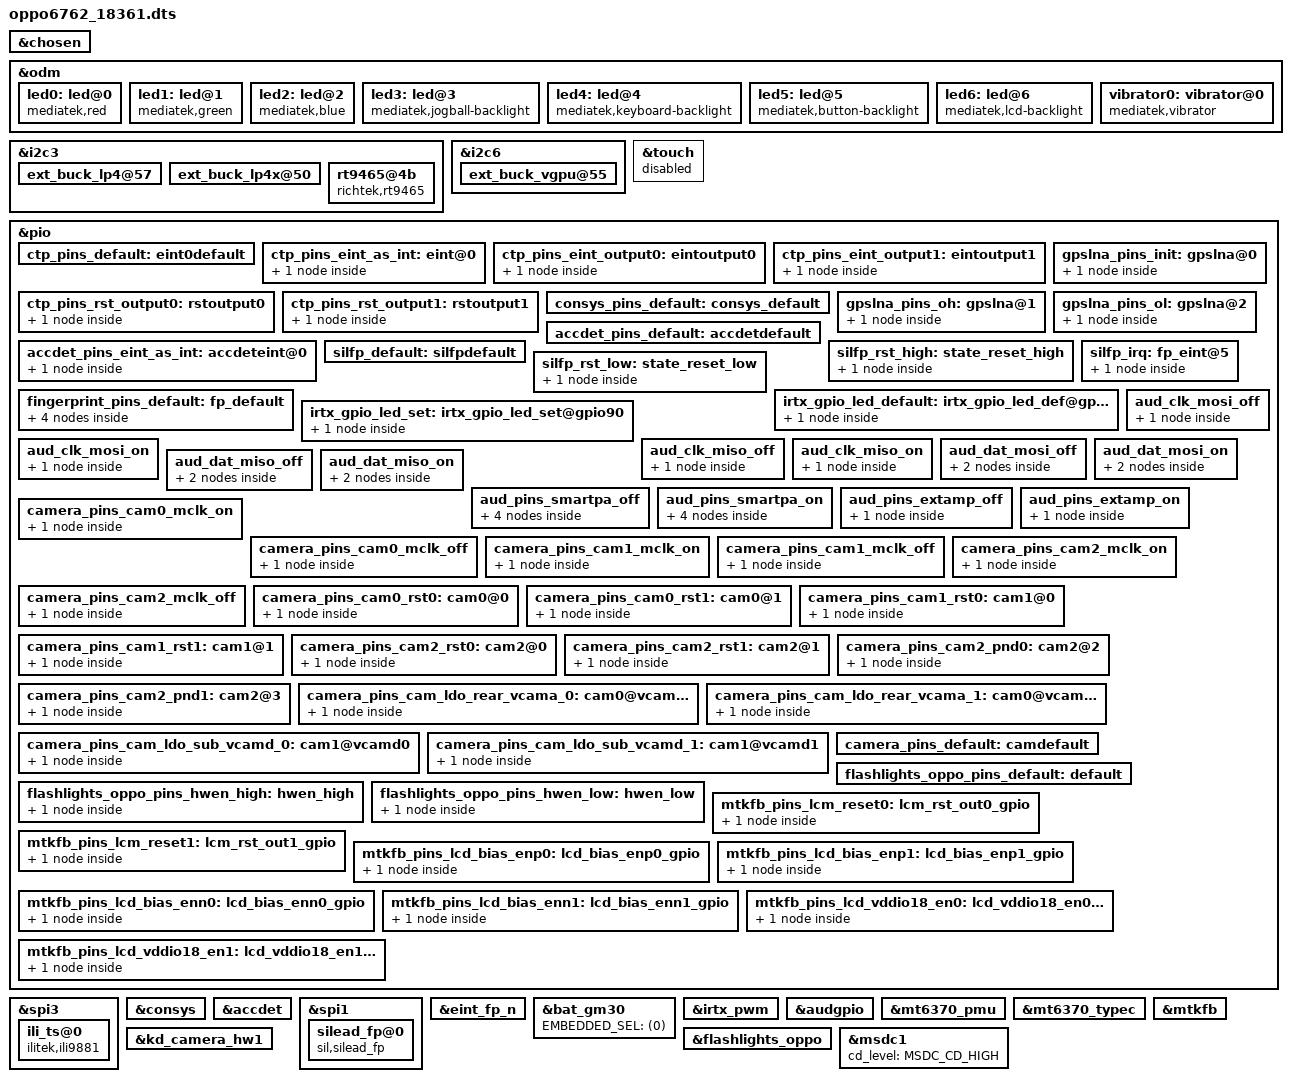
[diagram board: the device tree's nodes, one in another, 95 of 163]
#include <dt-bindings/interrupt-controller/arm-gic.h>
#include <dt-bindings/interrupt-controller/irq.h>
#include <dt-bindings/pinctrl/mt6765-pinfunc.h>
#include <dt-bindings/clock/mt6765-clk.h>
//#ifdef ODM_WT_EDIT
//Jinfan.Hu@ODM_WT.BSP.Storage.Sdcard, 2018/08/08, Modify for sdcard irq trigger states
#include <dt-bindings/mmc/mt6765-msdc.h>
//#endif

/dts-v1/;
/plugin/;

/* chosen */
&chosen {
	bootargs = "console=tty0 console=ttyS0,921600n1\
root=/dev/ram initrd=0x45000000,0x1000000 loglevel=8 \
androidboot.selinux=permissive androidboot.hardware=mt6765 \
initcall_debug=1 maxcpus=1";

	/* fpga may has no lk, we need to specify display info here */
	/* fb buffer is reserved using this dts by memory node above */
	atag,videolfb-fb_base_h = <0x0>;
	atag,videolfb-fb_base_l = <0x5e605000>;
	atag,videolfb-islcmfound = <1>;
	/* because no lk, so lcm is not inited */
	atag,videolfb-islcm_inited = <0>;
	atag,videolfb-fps= <6000>;
	atag,videolfb-vramSize= <0x017bb000>;
	atag,videolfb-lcmname= "nt35695B_fhd_dsi_cmd_auo_rt5081_drv";
};

&odm {
	led0:led@0 {
		compatible = "mediatek,red";
		led_mode = <0>;
		data = <1>;
		pwm_config = <0 0 0 0 0>;
	};
	led1:led@1 {
		compatible = "mediatek,green";
		led_mode = <0>;
		data = <1>;
		pwm_config = <0 0 0 0 0>;
	};
	led2:led@2 {
		compatible = "mediatek,blue";
		led_mode = <0>;
		data = <1>;
		pwm_config = <0 0 0 0 0>;
	};
	led3:led@3 {
		compatible = "mediatek,jogball-backlight";
		led_mode = <0>;
		data = <1>;
		pwm_config = <0 0 0 0 0>;
	};
	led4:led@4 {
		compatible = "mediatek,keyboard-backlight";
		led_mode = <0>;
		data = <1>;
		pwm_config = <0 0 0 0 0>;
	};
	led5:led@5 {
		compatible = "mediatek,button-backlight";
		led_mode = <0>;
		data = <1>;
		pwm_config = <0 0 0 0 0>;
	};
	led6:led@6 {
		compatible = "mediatek,lcd-backlight";
		led_mode = <4>;/* backlight control by LCM */
		data = <1>;
		pwm_config = <0 3 0 0 0>;
	};
	vibrator0:vibrator@0 {
		compatible = "mediatek,vibrator";
		vib_timer = <25>;
		vib_limit = <9>;
		vib_vol= <9>;
	};
};

&i2c3 {
	ext_buck_lp4@57 {
		regulator-name ="ext_buck_vdd2";
		regulator-min-microvolt = <300000>;
		regulator-max-microvolt = <1300000>;
		vsel_pin = <0>;
	};

	ext_buck_lp4x@50 {
		regulator-name ="ext_buck_vddq";
		regulator-min-microvolt = <300000>;
		regulator-max-microvolt = <1300000>;
		vsel_pin = <1>;
	};
};

&i2c6 {
	ext_buck_vgpu@55 {
		regulator-name ="ext_buck_vgpu";
		regulator-min-microvolt = <300000>;
		regulator-max-microvolt = <1300000>;
		vsel_pin = <2>;
	};
};
/* TOUCH start */
&touch {
	tpd-resolution = <1080 1920>;
	use-tpd-button = <0>;
	tpd-key-num = <3>;
	tpd-key-local= <139 172 158 0>;
	tpd-key-dim-local = <90 883 100 40 230
				 883 100 40 370 883 100 40 0 0 0 0>;
	tpd-max-touch-num = <5>;
	tpd-filter-enable = <1>;
	tpd-filter-pixel-density = <146>;
	tpd-filter-custom-prameters = <0 0 0 0 0 0 0 0 0 0 0 0>;
	tpd-filter-custom-speed = <0 0 0>;
	pinctrl-names = "default", "state_eint_as_int", "state_eint_output0",
		"state_eint_output1", "state_rst_output0", "state_rst_output1";
	pinctrl-0 = <&ctp_pins_default>;
	pinctrl-1 = <&ctp_pins_eint_as_int>;
	pinctrl-2 = <&ctp_pins_eint_output0>;
	pinctrl-3 = <&ctp_pins_eint_output1>;
	pinctrl-4 = <&ctp_pins_rst_output0>;
	pinctrl-5 = <&ctp_pins_rst_output1>;
//#ifdef ODM_WT_EDIT
//Bin.Su@ODM_WT.BSP.TouchScreen, 2018/08/09, Disable no use dts for TouchScreen BringUp
	status = "disable";
//#endif
};
&pio {
	ctp_pins_default: eint0default {
	};
	ctp_pins_eint_as_int: eint@0 {
		pins_cmd_dat {
			pinmux = <PINMUX_GPIO0__FUNC_GPIO0>;
			slew-rate = <0>;
			bias-disable;
		};
	};
	ctp_pins_eint_output0: eintoutput0 {
		pins_cmd_dat {
			pinmux = <PINMUX_GPIO0__FUNC_GPIO0>;
			slew-rate = <1>;
			output-low;
		};
	};
	ctp_pins_eint_output1: eintoutput1 {
		pins_cmd_dat {
			pinmux = <PINMUX_GPIO0__FUNC_GPIO0>;
			slew-rate = <1>;
			output-high;
		};
	};
	ctp_pins_rst_output0: rstoutput0 {
		pins_cmd_dat {
			pinmux = <PINMUX_GPIO174__FUNC_GPIO174>;
			slew-rate = <1>;
			output-low;
		};
	};
	ctp_pins_rst_output1: rstoutput1 {
		pins_cmd_dat {
			pinmux = <PINMUX_GPIO174__FUNC_GPIO174>;
			slew-rate = <1>;
			output-high;
		};
	};
};
/* TOUCH end */

//#ifdef ODM_WT_EDIT
//Bin.Su@ODM_WT.BSP.TouchScreen, 2018/08/09, Add dts for TouchScreen BringUp
/*SPI touch start*/
&spi3 {
	#address-cells = <1>;
	#size-cells = <0>;
	ili_ts@0 {
		reg = <0>;
		compatible = "ilitek,ili9881","mediatek,cap_touch";
		touch,irq-gpio = <&pio 0 0>;
		touch,reset-gpio = <&pio 174 0>;
		spi-max-frequency = <9600000>;
		/*netlink-event = <30>;*/
		/* touchpanel configuration */
		touchpanel,rst-gpio = <&pio 174 0x0>;
		touchpanel,irq-gpio = <&pio 0 0x0>;
		touchpanel,open_short_not_use_fw;

		pinctrl-names = "default", "state_eint_as_int", "state_eint_output0",
		"state_eint_output1", "state_rst_output0", "state_rst_output1";
		pinctrl-0 = <&ctp_pins_default>;
		pinctrl-1 = <&ctp_pins_eint_as_int>;
		pinctrl-2 = <&ctp_pins_eint_output0>;
		pinctrl-3 = <&ctp_pins_eint_output1>;
		pinctrl-4 = <&ctp_pins_rst_output0>;
		pinctrl-5 = <&ctp_pins_rst_output1>;
		status = "ok";
	};
};
/*SPI touch end*/
//#endif

/* CONSYS GPIO standardization */
&pio {
	consys_pins_default: consys_default {
	};
	gpslna_pins_init: gpslna@0 {
		pins_cmd_dat {
			pinmux = <PINMUX_GPIO91__FUNC_GPIO91>;
			//#ifndef VENDOR_EDIT
			//Wenjie.Liu@PSW.CN.GPS.Hardware.Power.1202743, 2017/12/29,
			//modify for: [GPS_LNA gpio's output direction is out]
			/*
			slew-rate = <0>;
			*/
			//#else /* VENDOR_EDIT */
			slew-rate = <1>;
			//#endif /* VENDOR_EDIT */
			bias-disable;
			output-low;
		};
	};
	gpslna_pins_oh: gpslna@1 {
		pins_cmd_dat {
			pinmux = <PINMUX_GPIO91__FUNC_GPIO91>;
			slew-rate = <1>;
			output-high;
		};
	};
	gpslna_pins_ol: gpslna@2 {
		pins_cmd_dat {
			pinmux = <PINMUX_GPIO91__FUNC_GPIO91>;
			slew-rate = <1>;
			output-low;
		};
	};
};
&consys {
	pinctrl-names = "default", "gps_lna_state_init",
		"gps_lna_state_oh", "gps_lna_state_ol";
	pinctrl-0 = <&consys_pins_default>;
	pinctrl-1 = <&gpslna_pins_init>;
	pinctrl-2 = <&gpslna_pins_oh>;
	pinctrl-3 = <&gpslna_pins_ol>;
	status = "okay";
};
/* CONSYS end */

/* accdet start */
//#ifdef VENDOR_EDIT
//Yongzhi.Zhang@PSW.MM.AudioDriver.Codec.1309324, 2018/10/25,
//modify for changing micbias vol to 2.7V for headset mic
&accdet {
	accdet-mic-vol = <7>;
	headset-mode-setting = <0x500 0x500 1 0x1f0 0x800 0x800 0x20 0x44>;
	accdet-plugout-debounce = <1>;
	accdet-mic-mode = <1>;
	headset-eint-level-pol = <8>;
	headset-three-key-threshold = <0 82 170 306>;
	headset-three-key-threshold-CDD = <0 121 192 600>;
	headset-four-key-threshold = <0 58 121 192 400>;
	pinctrl-names = "default", "state_eint_as_int";
	pinctrl-0 = <&accdet_pins_default>;
	pinctrl-1 = <&accdet_pins_eint_as_int>;
	status = "okay";
};
//#else /* VENDOR_EDIT */
/*
&accdet {
	accdet-mic-vol = <6>;
	headset-mode-setting = <0x500 0x500 1 0x1f0 0x800 0x800 0x20 0x44>;
	accdet-plugout-debounce = <1>;
	accdet-mic-mode = <1>;
	headset-eint-level-pol = <8>;
	headset-three-key-threshold = <0 80 220 400>;
	headset-three-key-threshold-CDD = <0 121 192 600>;
	headset-four-key-threshold = <0 58 121 192 400>;
	pinctrl-names = "default", "state_eint_as_int";
	pinctrl-0 = <&accdet_pins_default>;
	pinctrl-1 = <&accdet_pins_eint_as_int>;
	status = "okay";
};
*/
//#endif /* VENDOR_EDIT */
&pio {
	accdet_pins_default: accdetdefault {
	};
	accdet_pins_eint_as_int: accdeteint@0 {
		pins_cmd_dat {
			pinmux = <PINMUX_GPIO9__FUNC_GPIO9>;
			slew-rate = <0>;
			bias-disable;
		};
	};
};
/* accdet end */

//#ifdef ODM_WT_EDIT
//#Feng.Zhao@ODM_WT.BSP.Fingerprint.Basic, 2018/08/16, Modify for Fingerprint bringup
/* FINGERPRINT start */
/*&spi0 {
	#address-cells = <1>;
	#size-cells = <0>;
	fingerprint@0 {
		compatible = "goodix,goodix-fp";
		reg = <0>;
		spi-max-frequency = <8000000>;
		netlink-event = <30>;
		status = "okay";
	};
};

&goodix_fp {
	pinctrl-names = "default", "reset_high", "reset_low";
	pinctrl-0 = <&fingerprint_default>;
	pinctrl-1 = <&fingerprint_reset_high>;
	pinctrl-2 = <&fingerprint_reset_low>;
	status = "okay";
};

&pio {
	fingerprint_default: state_default {
	};
	fingerprint_reset_high: state_reset_high {
		pins_cmd_dat {
			pinmux = <PINMUX_GPIO172__FUNC_GPIO172>;
			slew-rate = <1>;
			output-high;
		};
	};
	fingerprint_reset_low: state_reset_low {
		pins_cmd_dat {
			pinmux = <PINMUX_GPIO172__FUNC_GPIO172>;
			slew-rate = <1>;
			output-low;
		};
	};
};*/

&spi1 {
	#address-cells = <1>;
	#size-cells = <0>;

	silead_fp@0 {
		compatible = "sil,silead_fp";
		reg = <0>;
		spi-id = <1>;
		spi-irq = <5>;
		spi-reg = <11010000>;
		spi-max-frequency = <8000000>;
		#netlink-event = <30>;
		status = "okay";
	};
};

&eint_fp_n {
	pinctrl-names = "default", "rst-low", "rst-high" ,
	                "irq-init", "spi-default";
	pinctrl-0 = <&silfp_default>;
	pinctrl-1 = <&silfp_rst_low>;
	pinctrl-2 = <&silfp_rst_high>;
	pinctrl-3 = <&silfp_irq>;
	pinctrl-4 = <&fingerprint_pins_default>;
	status = "okay";
};

&pio {
	silfp_default: silfpdefault {
	};

	silfp_rst_high: state_reset_high {
		pins_cmd_dat {
			pinmux = <PINMUX_GPIO171__FUNC_GPIO171>;
			slew-rate = <1>;
			output-high;
		};
	};

	silfp_rst_low: state_reset_low {
		pins_cmd_dat {
			pinmux = <PINMUX_GPIO171__FUNC_GPIO171>;
			slew-rate = <1>;
			output-low;
		};
	};

	silfp_irq: fp_eint@5 {
		pins_cmd_dat {
			pinmux = <PINMUX_GPIO5__FUNC_GPIO5>;
			slew-rate = <0>;
			bias-disable;
		};
	};
	fingerprint_pins_default: fp_default {
		pins_cmd_dat {
			pinmux = <PINMUX_GPIO26__FUNC_SPI1_A_CSB>;
			slew-rate = <1>;
			bias-pull-up;
		};

		pins_cmd2_dat {
			pinmux = <PINMUX_GPIO28__FUNC_SPI1_A_CLK>;
			slew-rate = <1>;
			bias-pull-down;
		};

		pins_cmd3_dat {
			pinmux = <PINMUX_GPIO25__FUNC_SPI1_A_MI>;
			slew-rate = <0>;
			bias-pull-down;
		};

		pins_cmd4_dat {
			pinmux = <PINMUX_GPIO27__FUNC_SPI1_A_MO>;
			slew-rate = <1>;
			bias-pull-down;
		};
	};
};


/* FINGERPRINT end */
//#endif

/* battery end */
&bat_gm30 {
	EMBEDDED_SEL = <(0)>;
};
/* battery end */

/* IRTX GPIO end */
&irtx_pwm {
	pinctrl-names = "irtx_gpio_led_default", "irtx_gpio_led_set";
	pinctrl-0 = <&irtx_gpio_led_default>;
	pinctrl-1 = <&irtx_gpio_led_set>;
	status = "okay";
};
&pio {
	irtx_gpio_led_default:irtx_gpio_led_def@gpio90 {
		pins_cmd_dat {
			pinmux = <PINMUX_GPIO90__FUNC_GPIO90>;
			slew-rate = <1>;
			bias-disable;
			output-low;
			input-schmitt-enable = <0>;
		};
	};

	irtx_gpio_led_set:irtx_gpio_led_set@gpio90 {
		pins_cmd_dat {
			pinmux = <PINMUX_GPIO90__FUNC_PWM0>;
			slew-rate = <1>;
			output-high;
		};
	};
};
/* IRTX GPIO Settings -End */

/* AUDIO GPIO standardization */
&audgpio {
	//Gong.Chen@ODM_WT.mm.audiodriver.machine, 2018/08/10, Add for speaker
	pinctrl-names = "aud_clk_mosi_off",
			"aud_clk_mosi_on",
			"aud_clk_miso_off",
			"aud_clk_miso_on",
			"aud_dat_mosi_off",
			"aud_dat_mosi_on",
			"aud_dat_miso_off",
			"aud_dat_miso_on",
			"aud_smartpa_off",
			"aud_smartpa_on",
			"extamp-pulllow",
			"extamp-pullhigh";
	pinctrl-0 = <&aud_clk_mosi_off>;
	pinctrl-1 = <&aud_clk_mosi_on>;
	pinctrl-2 = <&aud_clk_miso_off>;
	pinctrl-3 = <&aud_clk_miso_on>;
	pinctrl-4 = <&aud_dat_mosi_off>;
	pinctrl-5 = <&aud_dat_mosi_on>;
	pinctrl-6 = <&aud_dat_miso_off>;
	pinctrl-7 = <&aud_dat_miso_on>;
	pinctrl-8 = <&aud_pins_smartpa_off>;
	pinctrl-9 = <&aud_pins_smartpa_on>;
	pinctrl-10 = <&aud_pins_extamp_off>;
	pinctrl-11 = <&aud_pins_extamp_on>;
	status = "okay";
};

&pio {
	aud_clk_mosi_off: aud_clk_mosi_off {
		pins_cmd0_dat {
			pinmux = <PINMUX_GPIO136__FUNC_GPIO136>;
		};
	};

	aud_clk_mosi_on: aud_clk_mosi_on {
		pins_cmd0_dat {
			pinmux = <PINMUX_GPIO136__FUNC_AUD_CLK_MOSI>;
		};
	};

	aud_clk_miso_off: aud_clk_miso_off {
		pins_cmd0_dat {
			pinmux = <PINMUX_GPIO140__FUNC_GPIO140>;
		};
	};

	aud_clk_miso_on: aud_clk_miso_on {
		pins_cmd0_dat {
			pinmux = <PINMUX_GPIO140__FUNC_AUD_CLK_MISO>;
		};
	};

	aud_dat_mosi_off: aud_dat_mosi_off {
		pins_cmd1_dat {
			pinmux = <PINMUX_GPIO138__FUNC_GPIO138>;
			input-enable;
			slew-rate = <0>;
			bias-disable;
		};
		pins_cmd2_dat {
			pinmux = <PINMUX_GPIO139__FUNC_GPIO139>;
			input-enable;
			slew-rate = <0>;
			bias-disable;
		};
	};

	aud_dat_mosi_on: aud_dat_mosi_on {
		pins_cmd1_dat {
			pinmux = <PINMUX_GPIO138__FUNC_AUD_DAT_MOSI0>;
		};
		pins_cmd2_dat {
			pinmux = <PINMUX_GPIO139__FUNC_AUD_DAT_MOSI1>;
		};
	};

	aud_dat_miso_off: aud_dat_miso_off {
		pins_cmd1_dat {
			pinmux = <PINMUX_GPIO142__FUNC_GPIO142>;
			input-enable;
			slew-rate = <0>;
			bias-disable;
		};
		pins_cmd2_dat {
			pinmux = <PINMUX_GPIO143__FUNC_GPIO143>;
			input-enable;
			slew-rate = <0>;
			bias-disable;
		};
	};

	aud_dat_miso_on: aud_dat_miso_on {
		pins_cmd1_dat {
			pinmux = <PINMUX_GPIO142__FUNC_AUD_DAT_MISO0>;
		};
		pins_cmd2_dat {
			pinmux = <PINMUX_GPIO143__FUNC_AUD_DAT_MISO1>;
		};
	};

	aud_pins_smartpa_off: aud_pins_smartpa_off {
		pins_cmd0_dat {
			pinmux = <PINMUX_GPIO17__FUNC_GPIO17>;
		};
		pins_cmd1_dat {
			pinmux = <PINMUX_GPIO18__FUNC_GPIO18>;
		};
		pins_cmd2_dat {
			pinmux = <PINMUX_GPIO19__FUNC_GPIO19>;
		};
		pins_cmd3_dat {
			pinmux = <PINMUX_GPIO20__FUNC_GPIO20>;
		};
	};

	aud_pins_smartpa_on: aud_pins_smartpa_on {
		pins_cmd0_dat {
			pinmux = <PINMUX_GPIO17__FUNC_I2S0_DI>;
		};
		pins_cmd1_dat {
			pinmux = <PINMUX_GPIO18__FUNC_I2S3_BCK>;
		};
		pins_cmd2_dat {
			pinmux = <PINMUX_GPIO19__FUNC_I2S3_LRCK>;
		};
		pins_cmd3_dat {
			pinmux = <PINMUX_GPIO20__FUNC_I2S3_DO>;
		};
	};

	//#ifdef ODM_WT_EDIT
	//Gong.Chen@ODM_WT.mm.audiodriver.machine, 2018/08/10, Add for speaker
	aud_pins_extamp_off: aud_pins_extamp_off {
		pins_cmd_dat {
			pinmux = <PINMUX_GPIO159__FUNC_GPIO159>;
			slew-rate = <1>;
			output-low;
		};
	};

	aud_pins_extamp_on: aud_pins_extamp_on {
		pins_cmd_dat {
			pinmux = <PINMUX_GPIO159__FUNC_GPIO159>;
			slew-rate = <1>;
			output-high;
		};
	};
	//endif /* ODM_WT_EDIT */
};
/* AUDIO end */

&mt6370_pmu {
	mt6370,intr_gpio_num = <11>; /* direct defined GPIO num */
	mt6370,intr_gpio = <&pio 11 0x0>;
};

&mt6370_typec {
	mt6370pd,intr_gpio_num = <41>; /* direct defined GPIO num */
	mt6370pd,intr_gpio = <&pio 41 0x0>;
};


&i2c3 {
	rt9465@4b {
		compatible = "richtek,rt9465";
		reg = <0x4b>;
		status = "okay";
		rt,en_gpio_num = <176>;
		rt,en_gpio = <&pio 176 0x0>;
//Bin.Su@ODM_WT.BSP.TouchScreen, 2018/08/09, wrong gpio 23 dts for TouchScreen BringUp
		/*rt,intr_gpio_num = <23>;*//* direct defined GPIO num */
		/*rt,intr_gpio = <&pio 23 0x0>;*/
		interrupt-names = "wdtmri";
		charger_name = "secondary_chg";
		ichg = <1500000>; /* uA */
		mivr = <4500000>; /* uV */
		cv = <4550000>; /* uV */
		ieoc = <700000>; /* uA */
		safety_timer = <12>; /* hour */
		en_st; /* safety timer */
		/* en_te; */
		en_wdt;
	};
};

&pio {
	camera_pins_cam0_mclk_on: camera_pins_cam0_mclk_on {
		pins_cmd_dat {
			pinmux = <PINMUX_GPIO99__FUNC_CMMCLK0>;
		};
	};
	camera_pins_cam0_mclk_off: camera_pins_cam0_mclk_off {
		pins_cmd_dat {
			pinmux = <PINMUX_GPIO99__FUNC_GPIO99>;
		};
	};
	camera_pins_cam1_mclk_on: camera_pins_cam1_mclk_on {
		pins_cmd_dat {
			pinmux = <PINMUX_GPIO100__FUNC_CMMCLK1>;
		};
	};
	camera_pins_cam1_mclk_off: camera_pins_cam1_mclk_off {
		pins_cmd_dat {
			pinmux = <PINMUX_GPIO100__FUNC_GPIO100>;
		};
	};
	camera_pins_cam2_mclk_on: camera_pins_cam2_mclk_on {
		pins_cmd_dat {
			pinmux = <PINMUX_GPIO108__FUNC_CMMCLK2>;
		};
	};
	camera_pins_cam2_mclk_off: camera_pins_cam2_mclk_off {
		pins_cmd_dat {
			pinmux = <PINMUX_GPIO108__FUNC_GPIO108>;
		};
	};
	camera_pins_cam0_rst0: cam0@0 {
		pins_cmd_dat {
			pinmux = <PINMUX_GPIO101__FUNC_GPIO101>;
			slew-rate = <1>;
			output-low;
		};
	};
	camera_pins_cam0_rst1: cam0@1 {
		pins_cmd_dat {
			pinmux = <PINMUX_GPIO101__FUNC_GPIO101>;
			slew-rate = <1>;
			output-high;
		};
	};
	camera_pins_cam1_rst0: cam1@0 {
		pins_cmd_dat {
			pinmux = <PINMUX_GPIO102__FUNC_GPIO102>;
			slew-rate = <1>;
			output-low;
		};
	};
	camera_pins_cam1_rst1: cam1@1 {
		pins_cmd_dat {
			pinmux = <PINMUX_GPIO102__FUNC_GPIO102>;
			slew-rate = <1>;
			output-high;
		};
	};
	camera_pins_cam2_rst0: cam2@0 {
		pins_cmd_dat {
			pinmux = <PINMUX_GPIO109__FUNC_GPIO109>;
			slew-rate = <1>;
			output-low;
		};
	};
	camera_pins_cam2_rst1: cam2@1 {
		pins_cmd_dat {
			pinmux = <PINMUX_GPIO109__FUNC_GPIO109>;
			slew-rate = <1>;
			output-high;
		};
	};
	camera_pins_cam2_pnd0: cam2@2 {
		pins_cmd_dat {
			pinmux = <PINMUX_GPIO107__FUNC_GPIO107>;
			slew-rate = <1>;
			output-low;
		};
	};
	camera_pins_cam2_pnd1: cam2@3 {
		pins_cmd_dat {
			pinmux = <PINMUX_GPIO107__FUNC_GPIO107>;
			slew-rate = <1>;
			output-high;
		};
	};
	camera_pins_cam_ldo_rear_vcama_0: cam0@vcama0 {
		pins_cmd_dat {
			pinmux = <PINMUX_GPIO175__FUNC_GPIO175>;
			slew-rate = <1>;
			output-low;
		};
	};
	camera_pins_cam_ldo_rear_vcama_1: cam0@vcama1 {
		pins_cmd_dat {
			pinmux = <PINMUX_GPIO175__FUNC_GPIO175>;
			slew-rate = <1>;
			output-high;
		};
	};
	camera_pins_cam_ldo_sub_vcamd_0: cam1@vcamd0 {
		pins_cmd_dat {
			pinmux = <PINMUX_GPIO167__FUNC_GPIO167>;
			slew-rate = <1>;
			output-low;
		};
	};
	camera_pins_cam_ldo_sub_vcamd_1: cam1@vcamd1 {
		pins_cmd_dat {
			pinmux = <PINMUX_GPIO167__FUNC_GPIO167>;
			slew-rate = <1>;
			output-high;
		};
	};
	camera_pins_default: camdefault {
	};

};

&kd_camera_hw1 {
	camera,vcam_id = <&pio 178 0>;
	pinctrl-names = "default",
			"cam0_rst0",
			"cam0_rst1",
			"cam1_rst0",
			"cam1_rst1",
			"cam2_rst0",
			"cam2_rst1",
			"cam2_pnd0",
			"cam2_pnd1",
			"cam0_vcama_on",
			"cam0_vcama_off",
			"cam1_vcamd_on",
			"cam1_vcamd_off",
			"cam0_mclk_on",
			"cam0_mclk_off",
			"cam1_mclk_on",
			"cam1_mclk_off",
			"cam2_mclk_on",
			"cam2_mclk_off";

	pinctrl-0 = <&camera_pins_default>;
	pinctrl-1 = <&camera_pins_cam0_rst0>;
	pinctrl-2 = <&camera_pins_cam0_rst1>;
	pinctrl-3 = <&camera_pins_cam1_rst0>;
	pinctrl-4 = <&camera_pins_cam1_rst1>;
	pinctrl-5 = <&camera_pins_cam2_rst0>;
	pinctrl-6 = <&camera_pins_cam2_rst1>;
	pinctrl-7 = <&camera_pins_cam2_pnd0>;
	pinctrl-8 = <&camera_pins_cam2_pnd1>;
	pinctrl-9 = <&camera_pins_cam_ldo_rear_vcama_1>;
	pinctrl-10 = <&camera_pins_cam_ldo_rear_vcama_0>;
	pinctrl-11 = <&camera_pins_cam_ldo_sub_vcamd_1>;
	pinctrl-12= <&camera_pins_cam_ldo_sub_vcamd_0>;
	pinctrl-13 = <&camera_pins_cam0_mclk_on>;
	pinctrl-14 = <&camera_pins_cam0_mclk_off>;
	pinctrl-15 = <&camera_pins_cam1_mclk_on>;
	pinctrl-16 = <&camera_pins_cam1_mclk_off>;
	pinctrl-17 = <&camera_pins_cam2_mclk_on>;
	pinctrl-18 = <&camera_pins_cam2_mclk_off>;
	status = "okay";
};

&flashlights_oppo {
        pinctrl-names = "default","hwen_high","hwen_low";
        pinctrl-0 = <&flashlights_oppo_pins_default>;
        pinctrl-1 = <&flashlights_oppo_pins_hwen_high>;
        pinctrl-2 = <&flashlights_oppo_pins_hwen_low>;
        status = "okay";
};

&pio {
        flashlights_oppo_pins_default:default {
		};
        flashlights_oppo_pins_hwen_high: hwen_high {
                pins_cmd_dat {
                        pinmux = <PINMUX_GPIO152__FUNC_GPIO152>;
                        slew-rate = <1>;
                        output-high;
                };
        };
        flashlights_oppo_pins_hwen_low: hwen_low {
                pins_cmd_dat {
                        pinmux = <PINMUX_GPIO152__FUNC_GPIO152>;
                        slew-rate = <1>;
                        output-low;
                };
        };
};

//#ifdef ODM_WT_EDIT
//Jinfan.Hu@ODM_WT.BSP.Storage.Sdcard, 2018/08/08, Modify for sdcard irq trigger states
&msdc1 {
	cd_level = /bits/ 8 <MSDC_CD_HIGH>;
};
//#endif
/* #ifdef ODM_WT_EDIT */
/* Benzhong.Hou@ODM_WT.MM.Display.Lcd, 2018/08/09, LCD voltage control */
/* DISPSYS GPIO standardization */
&mtkfb {
        pinctrl-names = "lcm_rst_out0_gpio", "lcm_rst_out1_gpio", "lcd_bias_enp0_gpio", "lcd_bias_enp1_gpio",
			"lcd_bias_enn0_gpio", "lcd_bias_enn1_gpio", "lcd_vddio18_en0_gpio", "lcd_vddio18_en1_gpio";

	pinctrl-0 = <&mtkfb_pins_lcm_reset0>;
	pinctrl-1 = <&mtkfb_pins_lcm_reset1>;
	pinctrl-2 = <&mtkfb_pins_lcd_bias_enp0>;
	pinctrl-3 = <&mtkfb_pins_lcd_bias_enp1>;
	pinctrl-4 = <&mtkfb_pins_lcd_bias_enn0>;
	pinctrl-5 = <&mtkfb_pins_lcd_bias_enn1>;
	pinctrl-6 = <&mtkfb_pins_lcd_vddio18_en0>;
	pinctrl-7 = <&mtkfb_pins_lcd_vddio18_en1>;
        status = "okay";
};

&pio {
        mtkfb_pins_lcm_reset0: lcm_rst_out0_gpio {
                pins_cmd_dat {
                        pinmux = <PINMUX_GPIO45__FUNC_GPIO45>;
                        slew-rate = <1>;
                        output-low;
                };
        };
        mtkfb_pins_lcm_reset1: lcm_rst_out1_gpio {
                pins_cmd_dat {
                        pinmux = <PINMUX_GPIO45__FUNC_GPIO45>;
                        slew-rate = <1>;
                        output-high;
                };
        };

	mtkfb_pins_lcd_bias_enp0: lcd_bias_enp0_gpio {
                pins_cmd_dat {
                        pinmux = <PINMUX_GPIO150__FUNC_GPIO150>;
                        slew-rate = <1>;
                        output-low;
                };
        };
	mtkfb_pins_lcd_bias_enp1: lcd_bias_enp1_gpio {
                pins_cmd_dat {
                        pinmux = <PINMUX_GPIO150__FUNC_GPIO150>;
                        slew-rate = <1>;
                        output-high;
                };
        };

	mtkfb_pins_lcd_bias_enn0: lcd_bias_enn0_gpio {
                pins_cmd_dat {
                        pinmux = <PINMUX_GPIO151__FUNC_GPIO151>;
                        slew-rate = <1>;
                        output-low;
                };
        };
	mtkfb_pins_lcd_bias_enn1: lcd_bias_enn1_gpio {
                pins_cmd_dat {
                        pinmux = <PINMUX_GPIO151__FUNC_GPIO151>;
                        slew-rate = <1>;
                        output-high;
                };
        };

	mtkfb_pins_lcd_vddio18_en0: lcd_vddio18_en0_gpio {
                pins_cmd_dat {
                        pinmux = <PINMUX_GPIO170__FUNC_GPIO170>;
                        slew-rate = <1>;
                        output-low;
                };
        };
	mtkfb_pins_lcd_vddio18_en1: lcd_vddio18_en1_gpio {
                pins_cmd_dat {
                        pinmux = <PINMUX_GPIO170__FUNC_GPIO170>;
                        slew-rate = <1>;
                        output-high;
                };
        };
};
/* Benzhong.Hou@ODM_WT.MM.Display.Lcd, 2018/08/09, LCD voltage control */
/* #endif */

#include <oppo6762_18361/cust.dtsi>
/*End of this file, DO NOT ADD ANYTHING HERE*/
